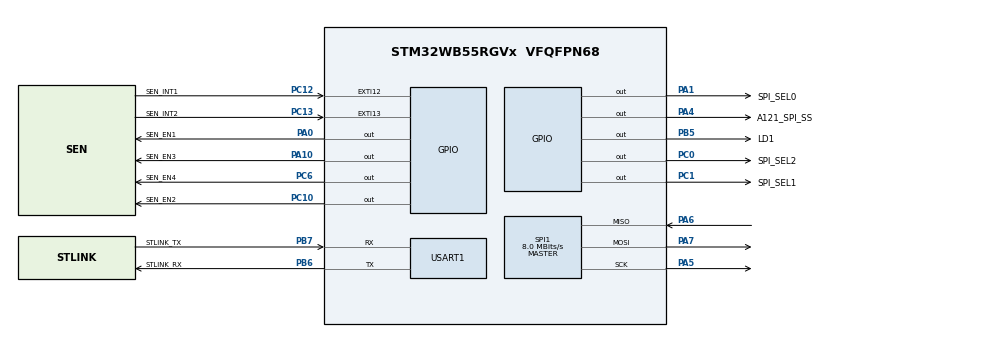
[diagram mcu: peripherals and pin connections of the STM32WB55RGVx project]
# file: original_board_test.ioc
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Mcu.Family=STM32WB
Mcu.Name=STM32WB55RGVx
Mcu.Package=VFQFPN68
NVIC.EXTI15_10_IRQn=true\:0\:0\:false\:false\:true\:true\:true\:true
NVIC.HSEM_IRQn=true\:0\:0\:false\:false\:true\:false\:true\:true
NVIC.IPCC_C1_RX_IRQn=true\:0\:0\:false\:false\:true\:true\:true\:true
NVIC.IPCC_C1_TX_IRQn=true\:0\:0\:false\:false\:true\:true\:true\:true
NVIC.PriorityGroup=NVIC_PRIORITYGROUP_4
NVIC.RTC_WKUP_IRQn=true\:0\:0\:false\:false\:true\:true\:true\:true
OSC_IN.GPIO_Label=RCC_OSC_IN
OSC_IN.Mode=HSE-External-Oscillator
OSC_IN.Signal=RCC_OSC_IN
OSC_OUT.GPIO_Label=RCC_OSC_OUT
OSC_OUT.Mode=HSE-External-Oscillator
OSC_OUT.Signal=RCC_OSC_OUT
PA0.GPIO_Label=SEN_EN1
PA0.GPIO_Speed=GPIO_SPEED_FREQ_VERY_HIGH
PA0.Signal=GPIO_Output
PA1.GPIO_Label=SPI_SEL0
PA1.GPIO_Speed=GPIO_SPEED_FREQ_VERY_HIGH
PA1.Signal=GPIO_Output
PA10.GPIO_Label=SEN_EN3
PA10.GPIO_Speed=GPIO_SPEED_FREQ_VERY_HIGH
PA10.Signal=GPIO_Output
PA13.GPIO_Label=JTMS
PA13.Signal=SYS_JTMS-SWDIO
PA14.GPIO_Label=JTCK
PA14.Signal=SYS_JTCK-SWCLK
PA4.GPIO_Label=A121_SPI_SS
PA4.GPIO_Speed=GPIO_SPEED_FREQ_VERY_HIGH
PA4.PinState=GPIO_PIN_SET
PA4.Signal=GPIO_Output
PA5.Mode=Full_Duplex_Master
PA5.Signal=SPI1_SCK
PA6.Mode=Full_Duplex_Master
PA6.Signal=SPI1_MISO
PA7.Mode=Full_Duplex_Master
PA7.Signal=SPI1_MOSI
PB3.GPIO_Label=JTDO
PB3.Signal=SYS_JTDO-SWO
PB5.GPIO_Label=LD1
PB5.Signal=GPIO_Output
PB6.GPIO_Label=STLINK_RX
PB6.Mode=Asynchronous
PB6.Signal=USART1_TX
PB7.GPIO_Label=STLINK_TX
PB7.Mode=Asynchronous
PB7.Signal=USART1_RX
PC0.GPIO_Label=SPI_SEL2
PC0.GPIO_Speed=GPIO_SPEED_FREQ_VERY_HIGH
PC0.Signal=GPIO_Output
PC1.GPIO_Label=SPI_SEL1
PC1.GPIO_Speed=GPIO_SPEED_FREQ_VERY_HIGH
PC1.Signal=GPIO_Output
PC10.GPIO_Label=SEN_EN2
PC10.GPIO_Speed=GPIO_SPEED_FREQ_VERY_HIGH
PC10.Signal=GPIO_Output
PC12.GPIO_Label=SEN_INT1
PC12.Signal=GPXTI12
PC13.GPIO_Label=SEN_INT2
PC13.Signal=GPXTI13
PC14-OSC32_IN.GPIO_Label=RCC_OSC32_IN
PC14-OSC32_IN.Mode=LSE-External-Oscillator
PC14-OSC32_IN.Signal=RCC_OSC32_IN
PC15-OSC32_OUT.GPIO_Label=RCC_OSC32_OUT
PC15-OSC32_OUT.Mode=LSE-External-Oscillator
PC15-OSC32_OUT.Signal=RCC_OSC32_OUT
PC6.GPIO_Label=SEN_EN4
PC6.GPIO_Speed=GPIO_SPEED_FREQ_VERY_HIGH
PC6.Signal=GPIO_Output
ProjectManager.HeapSize=0x200
ProjectManager.StackSize=0x400
ProjectManager.TargetToolchain=STM32CubeIDE
RCC.ADCFreq_Value=128000000
RCC.AHBFreq_Value=32000000
RCC.APB1Freq_Value=32000000
RCC.APB1TimFreq_Value=32000000
RCC.APB2Freq_Value=32000000
RCC.APB2TimFreq_Value=32000000
RCC.APB3Freq_Value=16000000
RCC.CortexFreq_Value=32000000
RCC.HCLKFreq_Value=32000000
RCC.HSE_VALUE=32000000
RCC.HSI48_VALUE=48000000
RCC.HSI_VALUE=16000000
RCC.MSIClockRange=RCC_MSIRANGE_10
RCC.RFWKPClockSelection=RCC_RFWKPCLKSOURCE_LSE
RCC.RTCClockSelection=RCC_RTCCLKSOURCE_LSE
RCC.SMPSCLockSelection=RCC_SMPSCLKSOURCE_HSI
RCC.SMPSCLockSelectionVirtual=RCC_SMPSCLKSOURCE_HSI
RCC.SMPSCLockSelectionVirtualVirtual=RCC_SMPSCLKSOURCE_HSI
RCC.SMPSDivider=1
RCC.SYSCLKFreq_VALUE=32000000
RCC.USBFreq_Value=128000000
RCC.VCOOutputFreq_Value=256000000
RF1.Mode=RF1_Activate
RF1.Signal=RF_RF1
SPI1.BaudRatePrescaler=SPI_BAUDRATEPRESCALER_4
SPI1.CalculateBaudRate=8.0 MBits/s
SPI1.DataSize=SPI_DATASIZE_8BIT
SPI1.Direction=SPI_DIRECTION_2LINES
SPI1.Mode=SPI_MODE_MASTER
SPI1.VirtualType=VM_MASTER
STM32_WPAN.AD_TYPE_COMPLETE_LOCAL_NAME=MonashMap
STM32_WPAN.AD_TYPE_COMPLETE_LOCAL_NAME_LENGTH=10
STM32_WPAN.BLE_STACK=FULL
STM32_WPAN.CFG_BONDING_MODE=0
STM32_WPAN.CFG_FAST_CONN_ADV_INTERVAL_MAX=100
STM32_WPAN.CFG_FAST_CONN_ADV_INTERVAL_MIN=80
STM32_WPAN.CFG_LSCLK_LSE=0
STM32_WPAN.CFG_TX_POWER=(0x18) /* -0.15dBm */
STM32_WPAN.CUSTOM_P2P_SERVER=Disabled
STM32_WPAN.CUSTOM_TEMPLATE=Enabled
STM32_WPAN.INCLUDE_AD_TYPE_COMPLETE_LOCAL_NAME=1
STM32_WPAN.NUMBER_OF_SERVICES=1
STM32_WPAN.PAIRING_PARAMETERS=OFF
STM32_WPAN.SERVICE1_CHAR1_GATT_NOTIFY_READ_REQ_AND_WAIT_FOR_APPL_RESP=\ 
STM32_WPAN.SERVICE1_CHAR1_GATT_NOTIFY_WRITE_REQ_AND_WAIT_FOR_APPL_RESP=\ 
STM32_WPAN.SERVICE1_CHAR1_LONG_NAME=myCharWrite
STM32_WPAN.SERVICE1_CHAR1_PROP_WRITE=CHAR_PROP_WRITE
STM32_WPAN.SERVICE1_CHAR1_SHORT_NAME=myCharWrite
STM32_WPAN.SERVICE1_CHAR2_GATT_NOTIFY_READ_REQ_AND_WAIT_FOR_APPL_RESP=\ 
STM32_WPAN.SERVICE1_CHAR2_GATT_NOTIFY_WRITE_REQ_AND_WAIT_FOR_APPL_RESP=\ 
STM32_WPAN.SERVICE1_CHAR2_LENGTH_CHARACTERISTIC=CHAR_VALUE_LEN_CONSTANT
STM32_WPAN.SERVICE1_CHAR2_LONG_NAME=myCharNotify
STM32_WPAN.SERVICE1_CHAR2_PROP_NOTIFY=CHAR_PROP_NOTIFY
STM32_WPAN.SERVICE1_CHAR2_PROP_WRITE_WITHOUT_RESP=CHAR_PROP_WRITE_WITHOUT_RESP
STM32_WPAN.SERVICE1_CHAR2_SHORT_NAME=myCharNotify
STM32_WPAN.SERVICE1_CHAR2_UUID=00 01
STM32_WPAN.SERVICE1_CHAR2_VALUE_LENGTH=512
STM32_WPAN.SERVICE1_LONG_NAME=mySvc
STM32_WPAN.SERVICE1_NUMBER_OF_CHARACTERISTICS=2
STM32_WPAN.SERVICE1_SHORT_NAME=mySvc
USART1.VirtualMode-Asynchronous=VM_ASYNC
VP_HSEM_VS_HSEM.Mode=HSEM_Activate
VP_IPCC_VS_IPCC.Mode=IPCC_Activate
VP_MEMORYMAP_VS_MEMORYMAP.Mode=CurAppReg
VP_RTC_VS_RTC_Activate.Mode=RTC_Enabled
VP_RTC_VS_RTC_WakeUp_intern.Mode=WakeUp
VP_SEQUENCER_VS_SEQUENCER.Mode=SEQUENCER_Enabled
VP_STM32_WPAN_VS_BLE_HOST.Mode=STM32_WPAN_Enabled
VP_TINY_LPM_VS_TINY_LPM.Mode=TINY_LPM_Enabled
board=NUCLEO-WB55RG

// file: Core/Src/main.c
/* USER CODE BEGIN Header */
/**
  ******************************************************************************
  * @file           : main.c
  * @brief          : Main program body
  ******************************************************************************
  * @attention
  *
  * Copyright (c) 2024 STMicroelectronics.
  * All rights reserved.
  *
  * This software is licensed under terms that can be found in the LICENSE file
  * in the root directory of this software component.
  * If no LICENSE file comes with this software, it is provided AS-IS.
  *
  ******************************************************************************
  */
/* USER CODE END Header */
#include "main.h"

IPCC_HandleTypeDef hipcc;

RTC_HandleTypeDef hrtc;

SPI_HandleTypeDef hspi1;

UART_HandleTypeDef huart1;

void SystemClock_Config(void);
void PeriphCommonClock_Config(void);
static void MX_GPIO_Init(void);
static void MX_SPI1_Init(void);
static void MX_USART1_UART_Init(void);
static void MX_IPCC_Init(void);
static void MX_RTC_Init(void);
static void MX_RF_Init(void);

/* USER CODE BEGIN 0 */
int _write(int file, char *ptr, int len)
{
    (void)file;
    HAL_UART_Transmit(&huart1, (uint8_t*)ptr, len, 0xFFFF);
    return len;
}
/* USER CODE END 0 */

int main(void)
{

  /* MCU Configuration--------------------------------------------------------*/

  /* Reset of all peripherals, Initializes the Flash interface and the Systick. */
  HAL_Init();
  /* Config code for STM32_WPAN (HSE Tuning must be done before system clock configuration) */
  MX_APPE_Config();

  /* Configure the system clock */
  SystemClock_Config();

  /* Configure the peripherals common clocks */
  PeriphCommonClock_Config();

  /* IPCC initialisation */
  MX_IPCC_Init();

  /* Initialize all configured peripherals */
  MX_GPIO_Init();
  MX_SPI1_Init();
  MX_USART1_UART_Init();
  MX_RTC_Init();
  MX_RF_Init();
  /* USER CODE BEGIN 2 */
//  acc_example_service (0 , NULL ) ;
  /* USER CODE END 2 */

  /* Init code for STM32_WPAN */
  MX_APPE_Init();

  /* Infinite loop */
  /* USER CODE BEGIN WHILE */
  while (1)
  {
//	  HAL_GPIO_TogglePin(LD1_GPIO_Port,LD1_Pin);
//	  HAL_Delay(1000);
//	  printf("sFGSSSSSDF\n");
    /* USER CODE END WHILE */
    MX_APPE_Process();

  }
}

void SystemClock_Config(void)
{
  RCC_OscInitTypeDef RCC_OscInitStruct = {0};
  RCC_ClkInitTypeDef RCC_ClkInitStruct = {0};

  /** Configure LSE Drive Capability
  */
  HAL_PWR_EnableBkUpAccess();
  __HAL_RCC_LSEDRIVE_CONFIG(RCC_LSEDRIVE_MEDIUMHIGH);

  /** Configure the main internal regulator output voltage
  */
  __HAL_PWR_VOLTAGESCALING_CONFIG(PWR_REGULATOR_VOLTAGE_SCALE1);

  /** Initializes the RCC Oscillators according to the specified parameters
  * in the RCC_OscInitTypeDef structure.
  */
  RCC_OscInitStruct.OscillatorType = RCC_OSCILLATORTYPE_HSI|RCC_OSCILLATORTYPE_HSE
                              |RCC_OSCILLATORTYPE_LSE|RCC_OSCILLATORTYPE_MSI;
  RCC_OscInitStruct.HSEState = RCC_HSE_ON;
  RCC_OscInitStruct.LSEState = RCC_LSE_ON;
  RCC_OscInitStruct.HSIState = RCC_HSI_ON;
  RCC_OscInitStruct.MSIState = RCC_MSI_ON;
  RCC_OscInitStruct.HSICalibrationValue = RCC_HSICALIBRATION_DEFAULT;
  RCC_OscInitStruct.MSICalibrationValue = RCC_MSICALIBRATION_DEFAULT;
  RCC_OscInitStruct.MSIClockRange = RCC_MSIRANGE_10;
  RCC_OscInitStruct.PLL.PLLState = RCC_PLL_NONE;
  if (HAL_RCC_OscConfig(&RCC_OscInitStruct) != HAL_OK)
  {
    Error_Handler();
  }

  /** Configure the SYSCLKSource, HCLK, PCLK1 and PCLK2 clocks dividers
  */
  RCC_ClkInitStruct.ClockType = RCC_CLOCKTYPE_HCLK4|RCC_CLOCKTYPE_HCLK2
                              |RCC_CLOCKTYPE_HCLK|RCC_CLOCKTYPE_SYSCLK
                              |RCC_CLOCKTYPE_PCLK1|RCC_CLOCKTYPE_PCLK2;
  RCC_ClkInitStruct.SYSCLKSource = RCC_SYSCLKSOURCE_MSI;
  RCC_ClkInitStruct.AHBCLKDivider = RCC_SYSCLK_DIV1;
  RCC_ClkInitStruct.APB1CLKDivider = RCC_HCLK_DIV1;
  RCC_ClkInitStruct.APB2CLKDivider = RCC_HCLK_DIV1;
  RCC_ClkInitStruct.AHBCLK2Divider = RCC_SYSCLK_DIV1;
  RCC_ClkInitStruct.AHBCLK4Divider = RCC_SYSCLK_DIV1;

  if (HAL_RCC_ClockConfig(&RCC_ClkInitStruct, FLASH_LATENCY_1) != HAL_OK)
  {
    Error_Handler();
  }
}

void PeriphCommonClock_Config(void)
{
  RCC_PeriphCLKInitTypeDef PeriphClkInitStruct = {0};

  /** Initializes the peripherals clock
  */
  PeriphClkInitStruct.PeriphClockSelection = RCC_PERIPHCLK_SMPS|RCC_PERIPHCLK_RFWAKEUP;
  PeriphClkInitStruct.RFWakeUpClockSelection = RCC_RFWKPCLKSOURCE_LSE;
  PeriphClkInitStruct.SmpsClockSelection = RCC_SMPSCLKSOURCE_HSI;
  PeriphClkInitStruct.SmpsDivSelection = RCC_SMPSCLKDIV_RANGE0;

  if (HAL_RCCEx_PeriphCLKConfig(&PeriphClkInitStruct) != HAL_OK)
  {
    Error_Handler();
  }
}

static void MX_IPCC_Init(void)
{

  hipcc.Instance = IPCC;
  if (HAL_IPCC_Init(&hipcc) != HAL_OK)
  {
    Error_Handler();
  }

}

static void MX_RF_Init(void)
{

}

static void MX_RTC_Init(void)
{

  /** Initialize RTC Only
  */
  hrtc.Instance = RTC;
  hrtc.Init.HourFormat = RTC_HOURFORMAT_24;
  hrtc.Init.AsynchPrediv = CFG_RTC_ASYNCH_PRESCALER;
  hrtc.Init.SynchPrediv = CFG_RTC_SYNCH_PRESCALER;
  hrtc.Init.OutPut = RTC_OUTPUT_DISABLE;
  hrtc.Init.OutPutPolarity = RTC_OUTPUT_POLARITY_HIGH;
  hrtc.Init.OutPutType = RTC_OUTPUT_TYPE_OPENDRAIN;
  hrtc.Init.OutPutRemap = RTC_OUTPUT_REMAP_NONE;
  if (HAL_RTC_Init(&hrtc) != HAL_OK)
  {
    Error_Handler();
  }

  /** Enable the WakeUp
  */
  if (HAL_RTCEx_SetWakeUpTimer_IT(&hrtc, 0, RTC_WAKEUPCLOCK_RTCCLK_DIV16) != HAL_OK)
  {
    Error_Handler();
  }

}

static void MX_SPI1_Init(void)
{

  /* SPI1 parameter configuration*/
  hspi1.Instance = SPI1;
  hspi1.Init.Mode = SPI_MODE_MASTER;
  hspi1.Init.Direction = SPI_DIRECTION_2LINES;
  hspi1.Init.DataSize = SPI_DATASIZE_8BIT;
  hspi1.Init.CLKPolarity = SPI_POLARITY_LOW;
  hspi1.Init.CLKPhase = SPI_PHASE_1EDGE;
  hspi1.Init.NSS = SPI_NSS_SOFT;
  hspi1.Init.BaudRatePrescaler = SPI_BAUDRATEPRESCALER_4;
  hspi1.Init.FirstBit = SPI_FIRSTBIT_MSB;
  hspi1.Init.TIMode = SPI_TIMODE_DISABLE;
  hspi1.Init.CRCCalculation = SPI_CRCCALCULATION_DISABLE;
  hspi1.Init.CRCPolynomial = 7;
  hspi1.Init.CRCLength = SPI_CRC_LENGTH_DATASIZE;
  hspi1.Init.NSSPMode = SPI_NSS_PULSE_ENABLE;
  if (HAL_SPI_Init(&hspi1) != HAL_OK)
  {
    Error_Handler();
  }

}

static void MX_USART1_UART_Init(void)
{

  huart1.Instance = USART1;
  huart1.Init.BaudRate = 115200;
  huart1.Init.WordLength = UART_WORDLENGTH_8B;
  huart1.Init.StopBits = UART_STOPBITS_1;
  huart1.Init.Parity = UART_PARITY_NONE;
  huart1.Init.Mode = UART_MODE_TX_RX;
  huart1.Init.HwFlowCtl = UART_HWCONTROL_NONE;
  huart1.Init.OverSampling = UART_OVERSAMPLING_16;
  huart1.Init.OneBitSampling = UART_ONE_BIT_SAMPLE_DISABLE;
  huart1.Init.ClockPrescaler = UART_PRESCALER_DIV1;
  huart1.AdvancedInit.AdvFeatureInit = UART_ADVFEATURE_NO_INIT;
  if (HAL_UART_Init(&huart1) != HAL_OK)
  {
    Error_Handler();
  }
  if (HAL_UARTEx_SetTxFifoThreshold(&huart1, UART_TXFIFO_THRESHOLD_1_8) != HAL_OK)
  {
    Error_Handler();
  }
  if (HAL_UARTEx_SetRxFifoThreshold(&huart1, UART_RXFIFO_THRESHOLD_1_8) != HAL_OK)
  {
    Error_Handler();
  }
  if (HAL_UARTEx_DisableFifoMode(&huart1) != HAL_OK)
  {
    Error_Handler();
  }

}

static void MX_GPIO_Init(void)
{
  GPIO_InitTypeDef GPIO_InitStruct = {0};

  /* GPIO Ports Clock Enable */
  __HAL_RCC_GPIOC_CLK_ENABLE();
  __HAL_RCC_GPIOA_CLK_ENABLE();
  __HAL_RCC_GPIOB_CLK_ENABLE();

  /*Configure GPIO pin Output Level */
  HAL_GPIO_WritePin(GPIOC, SPI_SEL2_Pin|SPI_SEL1_Pin|SEN_EN4_Pin|SEN_EN2_Pin, GPIO_PIN_RESET);

  /*Configure GPIO pin Output Level */
  HAL_GPIO_WritePin(GPIOA, SEN_EN1_Pin|SPI_SEL0_Pin|SEN_EN3_Pin, GPIO_PIN_RESET);

  /*Configure GPIO pin Output Level */
  HAL_GPIO_WritePin(A121_SPI_SS_GPIO_Port, A121_SPI_SS_Pin, GPIO_PIN_SET);

  /*Configure GPIO pin Output Level */
  HAL_GPIO_WritePin(LD1_GPIO_Port, LD1_Pin, GPIO_PIN_RESET);

  /*Configure GPIO pins : SEN_INT2_Pin SEN_INT1_Pin */
  GPIO_InitStruct.Pin = SEN_INT2_Pin|SEN_INT1_Pin;
  GPIO_InitStruct.Mode = GPIO_MODE_IT_RISING;
  GPIO_InitStruct.Pull = GPIO_NOPULL;
  HAL_GPIO_Init(GPIOC, &GPIO_InitStruct);

  /*Configure GPIO pins : SPI_SEL2_Pin SPI_SEL1_Pin SEN_EN4_Pin SEN_EN2_Pin */
  GPIO_InitStruct.Pin = SPI_SEL2_Pin|SPI_SEL1_Pin|SEN_EN4_Pin|SEN_EN2_Pin;
  GPIO_InitStruct.Mode = GPIO_MODE_OUTPUT_PP;
  GPIO_InitStruct.Pull = GPIO_NOPULL;
  GPIO_InitStruct.Speed = GPIO_SPEED_FREQ_VERY_HIGH;
  HAL_GPIO_Init(GPIOC, &GPIO_InitStruct);

  /*Configure GPIO pins : SEN_EN1_Pin SPI_SEL0_Pin A121_SPI_SS_Pin SEN_EN3_Pin */
  GPIO_InitStruct.Pin = SEN_EN1_Pin|SPI_SEL0_Pin|A121_SPI_SS_Pin|SEN_EN3_Pin;
  GPIO_InitStruct.Mode = GPIO_MODE_OUTPUT_PP;
  GPIO_InitStruct.Pull = GPIO_NOPULL;
  GPIO_InitStruct.Speed = GPIO_SPEED_FREQ_VERY_HIGH;
  HAL_GPIO_Init(GPIOA, &GPIO_InitStruct);

  /*Configure GPIO pin : LD1_Pin */
  GPIO_InitStruct.Pin = LD1_Pin;
  GPIO_InitStruct.Mode = GPIO_MODE_OUTPUT_PP;
  GPIO_InitStruct.Pull = GPIO_NOPULL;
  GPIO_InitStruct.Speed = GPIO_SPEED_FREQ_LOW;
  HAL_GPIO_Init(LD1_GPIO_Port, &GPIO_InitStruct);

  /* EXTI interrupt init*/
  HAL_NVIC_SetPriority(EXTI15_10_IRQn, 0, 0);
  HAL_NVIC_EnableIRQ(EXTI15_10_IRQn);

}

void Error_Handler(void)
{
  __disable_irq();
  while (1)
  {
  }
}
